# K1921VG7T register map
Vendor: NIIET; Series: K1921VKx; File version: 1.0
CPU: CM4 r0p1, Endian.LITTLE endian, MPU, FPU
Registers are 32-bit, read-write, reset 0x0 unless marked. A register's access mark holds for its fields unless they carry their own. Offsets are from the block's base; [hi:lo] are bit positions; lines under a group give offsets from that group; {n}, {i} and the like mark numbered series; 'fields as' and 'values as' point back to an identical list.

## DMA — DMA control registers
Base 0x50000000
{0x0+0x80*i} CH[{i}] (i=0..7) group
  0x00 SRC_PTR — Command register 0 (source pointer)
    [31:0] RD_ADDR — Start address of read buffer
  0x04 DST_PTR — Command register 1 (destination pointer)
    [31:0] WR_ADDR — Start address of write buffer
  0x08 NDTL — Command register 2 (number of data to transfer, linear mode)
    [9:0] BUFFER_SIZE — Size of buffer to transfer
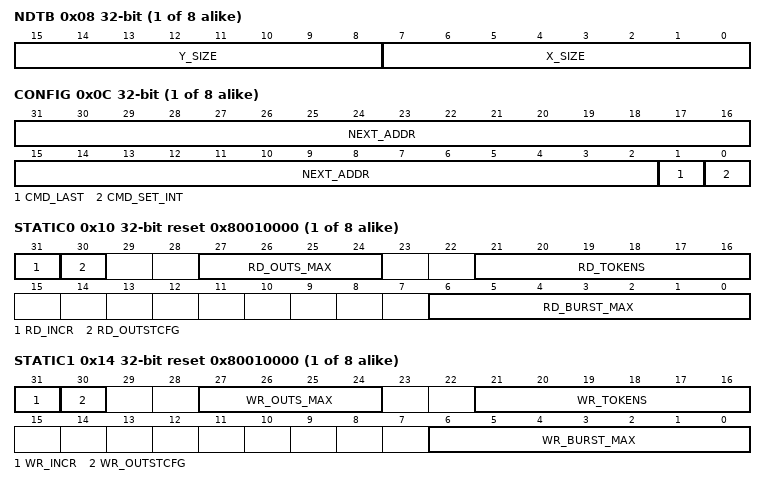
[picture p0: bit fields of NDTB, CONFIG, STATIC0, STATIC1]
  0x08 NDTB ro (alternate view of NDTL) — Command register 2 (number of data to transfer, block mode) - Not Implemented
    [15:8] Y_SIZE — Number of block lines - Not Implemented
    [7:0] X_SIZE — Block width. Value is in bytes and has no size restrictions - Not Implemented
  0x0C CONFIG — Command register 3 (config)
    [31:2] NEXT_ADDR — Address of next command
    [1] CMD_LAST — This is a last DMA command
    [0] CMD_SET_INT — Set interrupt after the entire buffer has been transferred
  0x10 STATIC0 reset 0x80010000 — Static register 0
    [31] RD_INCR — Increment next burst address
    [30] RD_OUTSTCFG ro — Channel cfg: Use AXI read command when FIFO is full - Not implemented
    [27:24] RD_OUTS_MAX — Number of maximum outstanding AXI read commands
    [21:16] RD_TOKENS — Number of AXI read commands to issue before the channel releases the AXI command bus
    [6:0] RD_BURST_MAX — Maximum number of bytes of an AXI read burst
  0x14 STATIC1 reset 0x80010000 — Static register 1
    [31] WR_INCR — Increment next burst address
    [30] WR_OUTSTCFG ro — Channel cfg: Use AXI write command when FIFO is full - Not implemented
    [27:24] WR_OUTS_MAX — Number of maximum outstanding AXI write commands
    [21:16] WR_TOKENS — Number of AXI write commands to issue before the channel releases the AXI command bus
    [6:0] WR_BURST_MAX — Maximum number of bytes of an AXI write burst
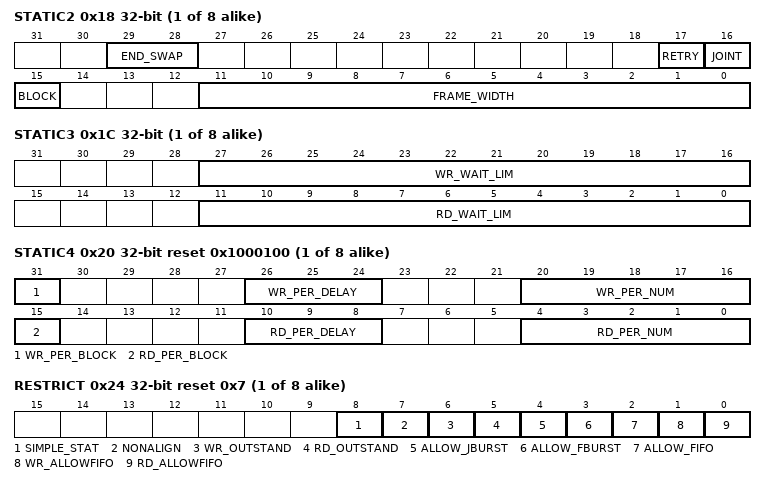
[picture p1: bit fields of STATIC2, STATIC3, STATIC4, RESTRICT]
  0x18 STATIC2 — Static register 2
    [29:28] END_SWAP — Endiannes byte swapping
      0=NO_SWAP (No swapping); 1=SWAP_WITHIN16bits (Swap bytes within 16 bits); 2=SWAP_WITHIN32bits (Swap bytes within 32 bits)
    [17] RETRY ro — If set the channel will automatically retry transfer if overflow or underflow occurs - Not implemented
    [16] JOINT — Channel works in joint mode
    [15] BLOCK ro — Work in block mode - Not Implemented
    [11:0] FRAME_WIDTH ro — Frame width for block mode - Not Implemented
  0x1C STATIC3 — Static register 3
    [27:16] WR_WAIT_LIM — Maximum number of cycles to wait after a channel is released and before its starts write command
    [11:0] RD_WAIT_LIM — Maximum number of cycles to wait after a channel is released and before its starts read command
  0x20 STATIC4 reset 0x1000100 — Static register 4
    [31] WR_PER_BLOCK — Peripheral control works in block mode
    [26:24] WR_PER_DELAY — Peripheral latency for AXI write operation (must be set more than 1 for work with perepherals)
    [20:16] WR_PER_NUM — Number of peripheral to write from
    [15] RD_PER_BLOCK — Peripheral control works in block mode
    [10:8] RD_PER_DELAY — Peripheral latency for AXI read operation (must be set more than 1 for work with perepherals)
    [4:0] RD_PER_NUM — Number of peripheral to read from
  0x24 RESTRICT ro reset 0x7 — Channels restrictions status register
    [8] SIMPLE_STAT — Configuration is aligned and perepherals are not used
    [7] NONALIGN — Block configuration is not aligned
    [6] WR_OUTSTAND — Write outstanding is currently active
    [5] RD_OUTSTAND — Read outstanding is currently active
    [4] ALLOW_JBURST — Joint bursts are currently active
    [3] ALLOW_FBURST — Maximum bursts of 16 strobes can be used
    [2] ALLOW_FIFO — Burst size can equal data buffer size
    [1] WR_ALLOWFIFO — Write start address does not restrict burst size
    [0] RD_ALLOWFIFO — Read start address does not restrict burst size
  0x28 RDOFFSET ro — Channels read offset status register
    [15:0] RD_OFFSET — Offset from the beginning of the buffer
  0x2C WROFFSET ro — Channels write offset status register
    [15:0] WR_OFFSET — Offset from the beginning of the buffer
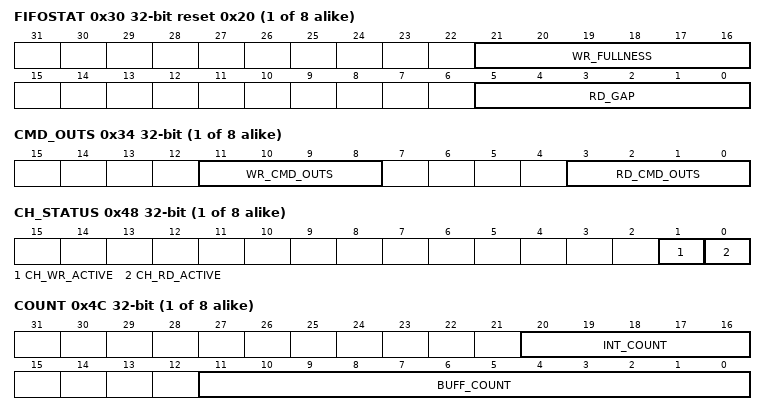
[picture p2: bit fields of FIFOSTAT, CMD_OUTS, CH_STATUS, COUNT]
  0x30 FIFOSTAT ro reset 0x20 — FIFO fullness status register
    [21:16] WR_FULLNESS — Occupied space in channels FIFO by write data
    [5:0] RD_GAP — Remaining space for channels FIFO for read data
  0x34 CMD_OUTS ro — Outstanding commands status register
    [11:8] WR_CMD_OUTS — Number of channels pending AXI write commands
    [3:0] RD_CMD_OUTS — Number of channels pending AXI read commands
  0x40 CH_ACTIVE reset 0x1 — Channel active register
    [0] CH_ACTIVE — Channel is currently active
  0x44 CH_START wo — Channel start register
    [0] CH_START — Start channel
  0x48 CH_STATUS ro — Channel status register
    [1] CH_WR_ACTIVE — Write on AXI bus is performed
    [0] CH_RD_ACTIVE — Read on AXI bus is performed
  0x4C COUNT ro — Buffer counter status register
    [20:16] INT_COUNT — Number of unserviced end interrupts
    [11:0] BUFF_COUNT — Number of buffers transferred by channel since started
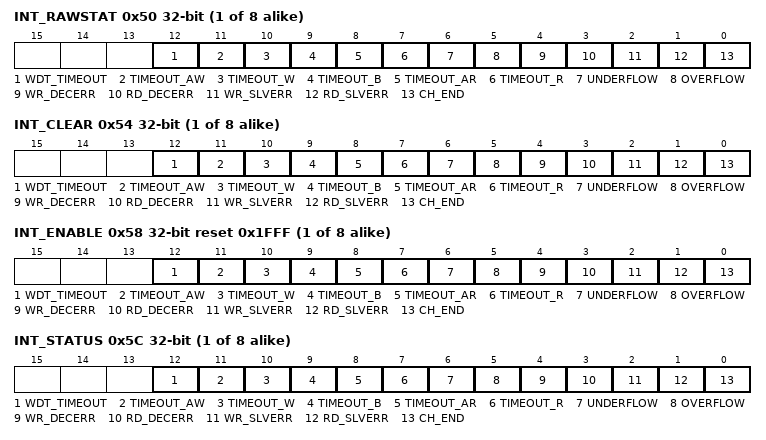
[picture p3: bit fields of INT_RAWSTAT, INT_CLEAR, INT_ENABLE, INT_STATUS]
  0x50 INT_RAWSTAT — Interrupt raw status register
    [12] WDT_TIMEOUT — Cnannel is active but did not start a burst for 2048 cycles
    [11] TIMEOUT_AW — A write issued by this channel caused a timeout on AXI write command bus
    [10] TIMEOUT_W — A write issued by this channel caused a timeout on AXI write data bus
    [9] TIMEOUT_B — A write issued by this channel caused a timeout on AXI write response bus
    [8] TIMEOUT_AR — A read issued by this channel caused a timeout on AXI read command bus
    [7] TIMEOUT_R — A read issued by this channel caused a timeout on AXI read data bus
    [6] UNDERFLOW — Data FIFO has been underflowed
    [5] OVERFLOW — Data FIFO has been overflowed
    [4] WR_DECERR — A write issued by this channel caused an AXI write decode error
    [3] RD_DECERR — A read issued by this channel caused an AXI read decode error
    [2] WR_SLVERR — A write issued by this channel caused an AXI write slave decode error
    [1] RD_SLVERR — A read issued by this channel caused an AXI read slave decode error
    [0] CH_END — Channel end interrupt
  0x54 INT_CLEAR wo — Interrupt clear register
    fields as CH[0].INT_RAWSTAT
  0x58 INT_ENABLE reset 0x1FFF — Interrupt enable register
    fields as CH[0].INT_RAWSTAT
  0x5C INT_STATUS ro — Interrupt status
    fields as CH[0].INT_RAWSTAT
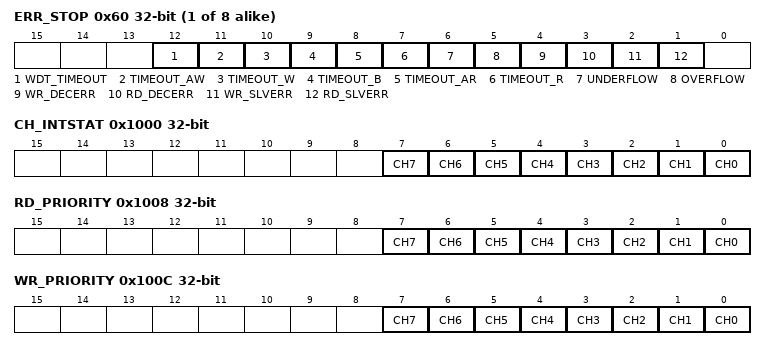
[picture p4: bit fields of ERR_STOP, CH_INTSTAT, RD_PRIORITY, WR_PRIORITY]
  0x60 ERR_STOP — Channel error stop condition register
    [12] WDT_TIMEOUT — If set, stop read and write transactions when this condition occurs
    [11] TIMEOUT_AW — If set, stop read and write transactions when this condition occurs
    [10] TIMEOUT_W — If set, stop read and write transactions when this condition occurs
    [9] TIMEOUT_B — If set, stop read and write transactions when this condition occurs
    [8] TIMEOUT_AR — If set, stop read and write transactions when this condition occurs
    [7] TIMEOUT_R — If set, stop read and write transactions when this condition occurs
    [6] UNDERFLOW — If set, stop read and write transactions when this condition occurs
    [5] OVERFLOW — If set, stop read and write transactions when this condition occurs
    [4] WR_DECERR — If set, stop read and write transactions when this condition occurs
    [3] RD_DECERR — If set, stop read and write transactions when this condition occurs
    [2] WR_SLVERR — If set, stop read and write transactions when this condition occurs
    [1] RD_SLVERR — If set, stop read and write transactions when this condition occurs
  0x64 ERR_RD_ADDR ro — Erroneous read transaction address register
    [31:0] ERR_ADDR — First encountered erroneous address in read transaction
  0x68 ERR_WR_ADDR ro — Erroneous write transaction address register
    [31:0] ERR_ADDR — First encountered erroneous address in write transaction
0x1000 CH_INTSTAT ro — Status register indicating which channels caused an interrupt on INT[7:0]
  [n] CH{n} (n=0..7) — Interrupt caused by Channel {n}
0x1004 CONTROL — DMA Core control arbitrage and mode
  [0] JOINT_MODE — Joint mode select
0x1008 RD_PRIORITY — DMA Core read priority channels
  [n] CH{n} (n=0..7) — Set the priority of channel {n}
0x100C WR_PRIORITY — DMA Core read priority channels
  [n] CH{n} (n=0..7) — Set the priority of channel {n}
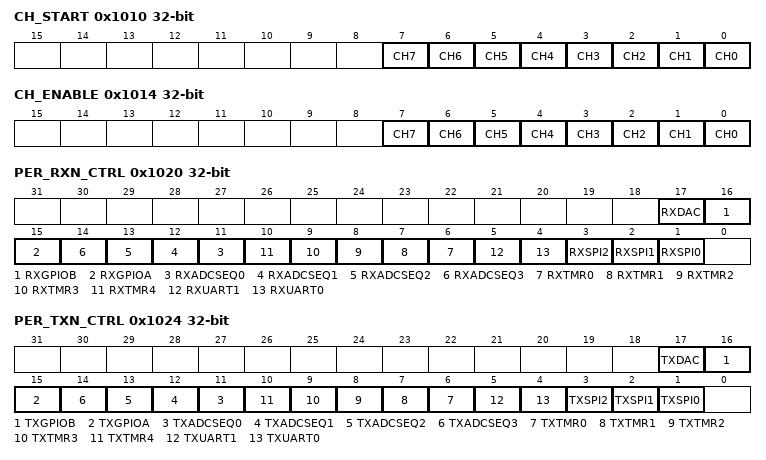
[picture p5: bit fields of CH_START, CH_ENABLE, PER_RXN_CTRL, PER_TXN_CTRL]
0x1010 CH_START wo — DMA channel start
  [n] CH{n} (n=0..7) — Start Channel {n}
0x1014 CH_ENABLE — DMA channel enable
  [n] CH{n} (n=0..7) — Enable Channel {n}
0x1018 IDLE ro reset 0x1 — Idle indication register
  [0] IDLE — IDLE Status
0x1020 PER_RX_CTRL — Direct control of peripheral RX request
  [17:1] RXREQ — Read requests {[unused] DAC, GPIOB, GPIOA, ADC Seq 3..0, TMR 4..0, UART 1..0, SPI 2..0}
0x1020 PER_RXN_CTRL (alternate view of PER_RX_CTRL) — Direct control of peripheral RX request (named bits)
  [17] RXDAC — [unused] Read request DAC
  [16] RXGPIOB — Read request GPIOB
  [15] RXGPIOA — Read request GPIOA
  [n+11] RXADCSEQ{n} (n=0..3) — Read request ADC Seq{n}
  [n+6] RXTMR{n} (n=0..4) — Read request TMR{n}
  [5] RXUART1 — Read request UART1
  [4] RXUART0 — Read request UART0
  [3] RXSPI2 — Read request SPI2
  [2] RXSPI1 — Read request SPI1
  [1] RXSPI0 — Read request SPI0
0x1024 PER_TX_CTRL — Direct control of peripheral TX request
  [17:1] TXREQ — Write requests {DAC, GPIOB, GPIOA, [unused] ADC Seq 3..0, TMR 4..0, UART 1..0, SPI 2..0}
0x1024 PER_TXN_CTRL (alternate view of PER_TX_CTRL) — Direct control of peripheral TX request (named bits)
  [17] TXDAC — Write request DAC
  [16] TXGPIOB — Write request GPIOB
  [15] TXGPIOA — Write request GPIOA
  [n+11] TXADCSEQ{n} (n=0..3) — [unused] Write request ADC Seq{n}
  [n+6] TXTMR{n} (n=0..4) — Write request TMR{n}
  [5] TXUART1 — Write request UART1
  [4] TXUART0 — Write request UART0
  [3] TXSPI2 — Write request SPI2
  [2] TXSPI1 — Write request SPI1
  [1] TXSPI0 — Write request SPI0
